# STM32L5x2 register map
File version: 1.3
Registers are 32-bit, read-write, reset 0x0 unless marked. A register's access mark holds for its fields unless they carry their own. Offsets are from the block's base; [hi:lo] are bit positions; {n}, {i} and the like mark numbered series.

## CRC — Cyclic redundancy check calculation unit
Base 0x40023000
Same registers: SEC_CRC 0x50023000
0x00 DR reset 0xFFFFFFFF — Data register
  [31:0] DR — Data register bits
0x04 IDR — Independent data register
  [7:0] IDR — General-purpose 8-bit data register bits
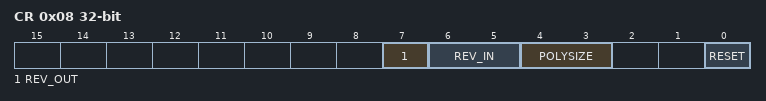
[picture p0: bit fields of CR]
0x08 CR access per field — Control register
  [7] REV_OUT rw — Reverse output data
  [6:5] REV_IN rw — Reverse input data
  [4:3] POLYSIZE rw — Polynomial size
  [0] RESET wo — RESET bit
0x10 INIT reset 0xFFFFFFFF — Initial CRC value
  [31:0] CRC_INIT — Programmable initial CRC value
0x14 POL reset 0x4C11DB7 — polynomial
  [31:0] Polynomialcoefficients — Programmable polynomial

## CRS — Clock recovery system
Base 0x40006000
Same registers: SEC_CRS 0x50006000
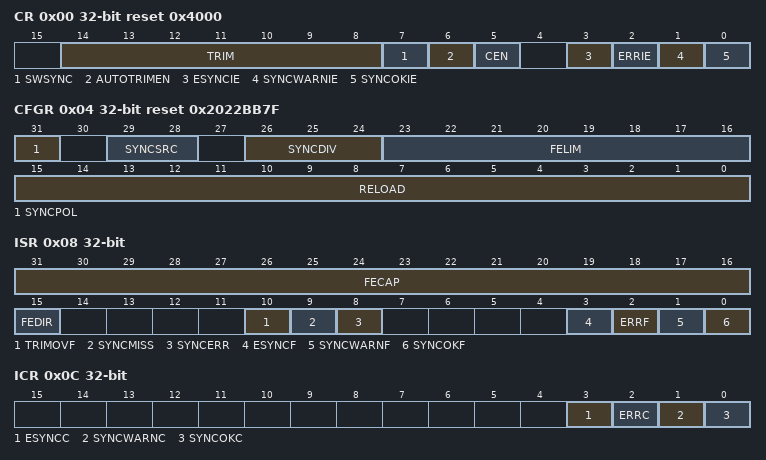
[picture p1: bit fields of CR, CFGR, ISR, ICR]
0x00 CR reset 0x4000 — control register
  [14:8] TRIM — HSI48 oscillator smooth trimming
  [7] SWSYNC — Generate software SYNC event
  [6] AUTOTRIMEN — Automatic trimming enable
  [5] CEN — Frequency error counter enable
  [3] ESYNCIE — Expected SYNC interrupt enable
  [2] ERRIE — Synchronization or trimming error interrupt enable
  [1] SYNCWARNIE — SYNC warning interrupt enable
  [0] SYNCOKIE — SYNC event OK interrupt enable
0x04 CFGR reset 0x2022BB7F — configuration register
  [31] SYNCPOL — SYNC polarity selection
  [29:28] SYNCSRC — SYNC signal source selection
  [26:24] SYNCDIV — SYNC divider
  [23:16] FELIM — Frequency error limit
  [15:0] RELOAD — Counter reload value
0x08 ISR ro — interrupt and status register
  [31:16] FECAP — Frequency error capture
  [15] FEDIR — Frequency error direction
  [10] TRIMOVF — Trimming overflow or underflow
  [9] SYNCMISS — SYNC missed
  [8] SYNCERR — SYNC error
  [3] ESYNCF — Expected SYNC flag
  [2] ERRF — Error flag
  [1] SYNCWARNF — SYNC warning flag
  [0] SYNCOKF — SYNC event OK flag
0x0C ICR — interrupt flag clear register
  [3] ESYNCC — Expected SYNC clear flag
  [2] ERRC — Error clear flag
  [1] SYNCWARNC — SYNC warning clear flag
  [0] SYNCOKC — SYNC event OK clear flag

## ADC_Common — Analog-to-Digital Converter
Base 0x42028300
Same registers: SEC_ADC_Common 0x52028300
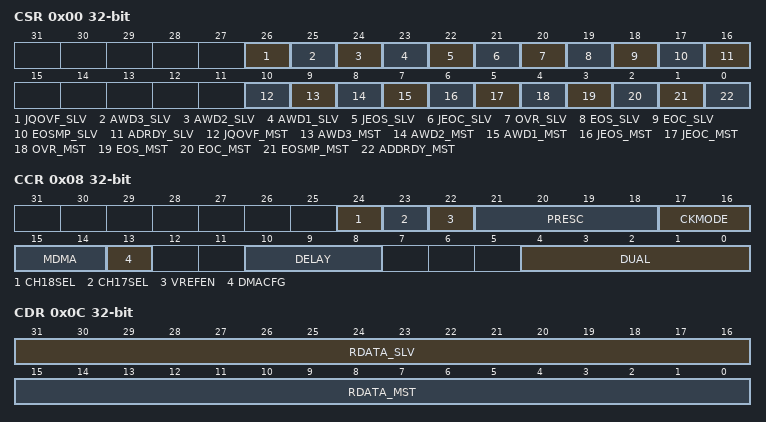
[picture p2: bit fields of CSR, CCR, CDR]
0x00 CSR ro — ADC Common status register
  [26] JQOVF_SLV, [25] AWD3_SLV, [24] AWD2_SLV, [23] AWD1_SLV, [22] JEOS_SLV, [21] JEOC_SLV, [20] OVR_SLV, [19] EOS_SLV, [18] EOC_SLV, [17] EOSMP_SLV, [16] ADRDY_SLV, [10] JQOVF_MST, [9] AWD3_MST, [8] AWD2_MST, [7] AWD1_MST, [6] JEOS_MST, [5] JEOC_MST, [4] OVR_MST, [3] EOS_MST, [2] EOC_MST, [1] EOSMP_MST, [0] ADDRDY_MST
0x08 CCR — ADC common control register
  [24] CH18SEL
  [23] CH17SEL
  [22] VREFEN — VREFINT enable
  [21:18] PRESC — ADC prescaler
  [17:16] CKMODE — ADC clock mode
  [15:14] MDMA
  [13] DMACFG
  [10:8] DELAY
  [4:0] DUAL
0x0C CDR ro — Common regular data register for dual mode
  [31:16] RDATA_SLV, [15:0] RDATA_MST

## ADC — Analog-to-Digital Converter
Base 0x42028000
Same registers: SEC_ADC 0x52028000
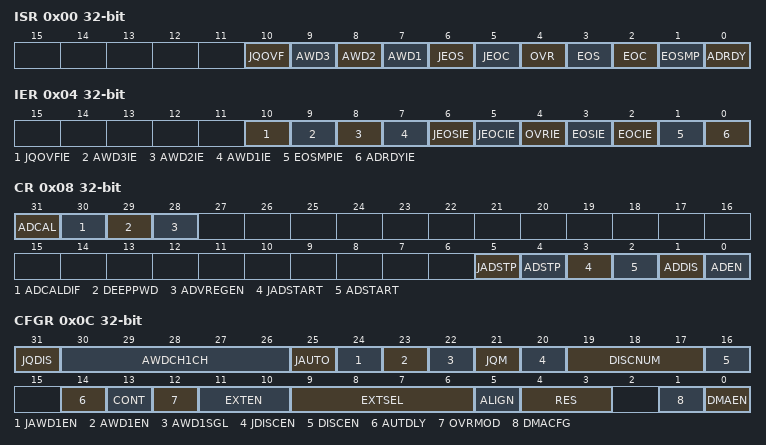
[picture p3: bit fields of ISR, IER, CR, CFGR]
0x00 ISR — interrupt and status register
  [10] JQOVF, [9] AWD3, [8] AWD2, [7] AWD1, [6] JEOS, [5] JEOC, [4] OVR, [3] EOS, [2] EOC, [1] EOSMP, [0] ADRDY
0x04 IER — interrupt enable register
  [10] JQOVFIE, [9] AWD3IE, [8] AWD2IE, [7] AWD1IE, [6] JEOSIE, [5] JEOCIE, [4] OVRIE, [3] EOSIE, [2] EOCIE, [1] EOSMPIE, [0] ADRDYIE
0x08 CR — control register
  [31] ADCAL, [30] ADCALDIF, [29] DEEPPWD, [28] ADVREGEN, [5] JADSTP, [4] ADSTP, [3] JADSTART, [2] ADSTART, [1] ADDIS, [0] ADEN
0x0C CFGR — configuration register
  [31] JQDIS, [30:26] AWDCH1CH, [25] JAUTO, [24] JAWD1EN, [23] AWD1EN, [22] AWD1SGL, [21] JQM, [20] JDISCEN, [19:17] DISCNUM, [16] DISCEN, [14] AUTDLY, [13] CONT, [12] OVRMOD, [11:10] EXTEN, [9:6] EXTSEL, [5] ALIGN, [4:3] RES, [1] DMACFG, [0] DMAEN
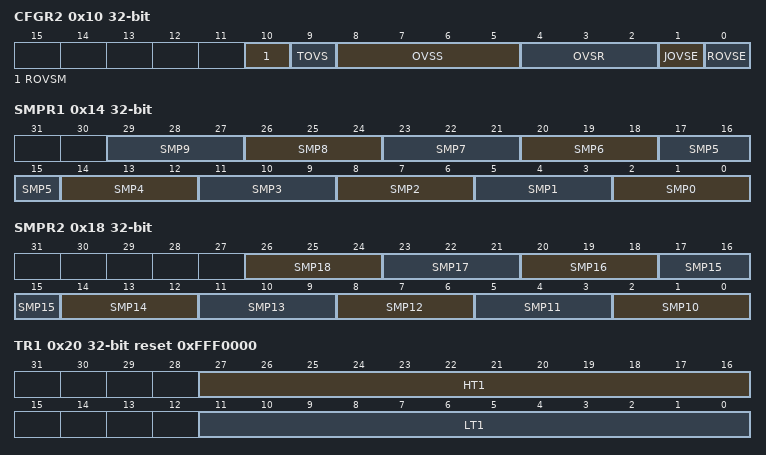
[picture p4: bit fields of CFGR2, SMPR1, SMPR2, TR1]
0x10 CFGR2 — configuration register
  [10] ROVSM — EXTEN
  [9] TOVS — EXTSEL
  [8:5] OVSS — ALIGN
  [4:2] OVSR — RES
  [1] JOVSE — DMACFG
  [0] ROVSE — DMAEN
0x14 SMPR1 — sample time register 1
  [3n+2:3n] SMP{n} (n=0..9)
0x18 SMPR2 — sample time register 2
  [3n-28:3n-30] SMP{n} (n=10..18)
0x20 TR1 reset 0xFFF0000 — watchdog threshold register 1
  [27:16] HT1, [11:0] LT1
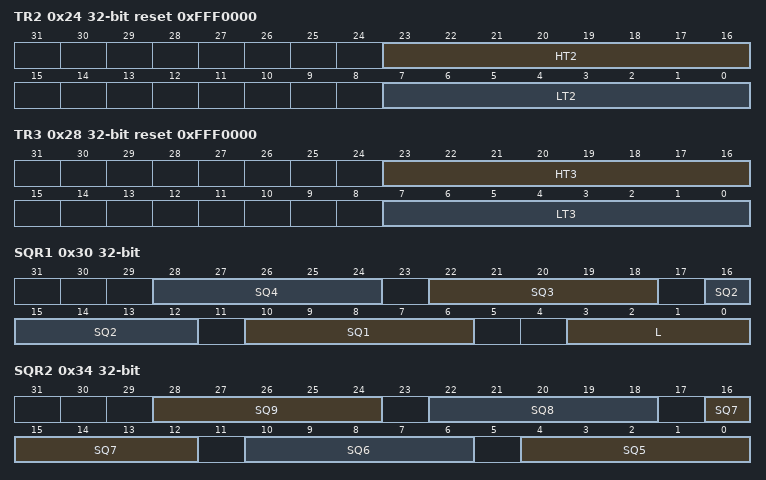
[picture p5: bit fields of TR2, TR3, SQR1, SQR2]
0x24 TR2 reset 0xFFF0000 — watchdog threshold register
  [23:16] HT2, [7:0] LT2
0x28 TR3 reset 0xFFF0000 — watchdog threshold register 3
  [23:16] HT3, [7:0] LT3
0x30 SQR1 — regular sequence register 1
  [6n+4:6n] SQ{n} (n=1..4), [3:0] L
0x34 SQR2 — regular sequence register 2
  [6n-26:6n-30] SQ{n} (n=5..9)
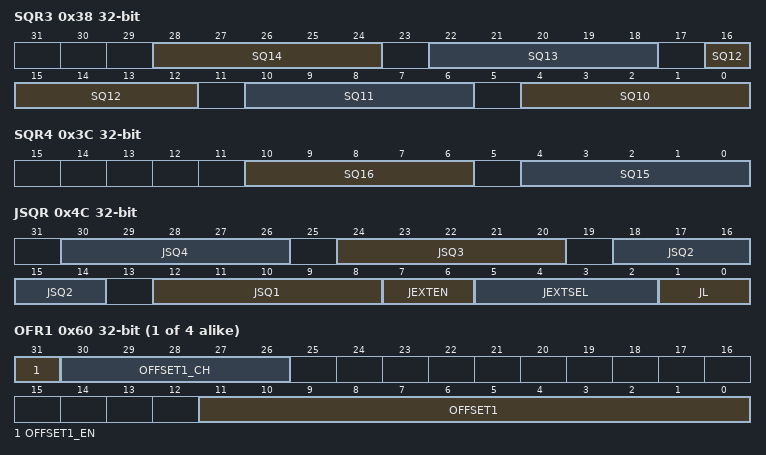
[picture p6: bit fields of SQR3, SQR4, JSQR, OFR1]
0x38 SQR3 — regular sequence register 3
  [6n-56:6n-60] SQ{n} (n=10..14)
0x3C SQR4 — regular sequence register 4
  [10:6] SQ16, [4:0] SQ15
0x40 DR ro — regular Data Register
  [15:0] RDATA — regularDATA
0x4C JSQR — injected sequence register
  [6n+6:6n+2] JSQ{n} (n=1..4), [7:6] JEXTEN, [5:2] JEXTSEL, [1:0] JL
{0x5C+4i} OFR{i} (i=1..4) — offset register {i}
  [31] OFFSET{i}_EN, [30:26] OFFSET{i}_CH, [11:0] OFFSET{i}
{0x7C+4i} JDR{i} ro (i=1..4) — injected data register {i}
  [15:0] JDATA — JDATA{i}
0xA0 AWD2CR — Analog Watchdog 2 Configuration Register
  [18:0] AWD2CH
0xA4 AWD3CR — Analog Watchdog 3 Configuration Register
  [18:0] AWD3CH
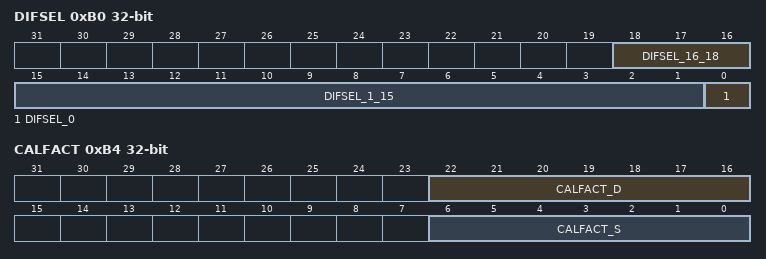
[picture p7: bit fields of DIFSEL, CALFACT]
0xB0 DIFSEL access per field — Differential Mode Selection Register 2
  [18:16] DIFSEL_16_18 ro — Differential mode for channels 18 to 16
  [15:1] DIFSEL_1_15 rw — Differential mode for channels 15 to 1
  [0] DIFSEL_0 ro — Differential mode for channel 0
0xB4 CALFACT — Calibration Factors
  [22:16] CALFACT_D, [6:0] CALFACT_S

## NVIC — Nested Vectored Interrupt Controller
Base 0xE000E100
{0x0+4i} ISER{i} (i=0..2) — Interrupt Set-Enable Register
  [31:0] SETENA
0x0C ISER3 — Interrupt Set-Enable Register
{0x80+4i} ICER{i} (i=0..2) — Interrupt Clear-Enable Register
  [31:0] CLRENA
0x8C ICER3 — Interrupt Clear-Enable Register
{0x100+4i} ISPR{i} (i=0..2) — Interrupt Set-Pending Register
  [31:0] SETPEND
0x10C ISPR3 — Interrupt Set-Pending Register
{0x180+4i} ICPR{i} (i=0..2) — Interrupt Clear-Pending Register
  [31:0] CLRPEND
0x18C ICPR3 — Interrupt Clear-Pending Register
{0x200+4i} IABR{i} ro (i=0..2) — Interrupt Active Bit Register
  [31:0] ACTIVE
0x20C IABR3 — Interrupt Active Bit Register
{0x280+4i} ITNS{i} (i=0..15)
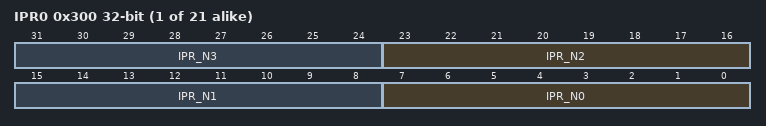
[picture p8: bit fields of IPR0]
{0x300+4i} IPR{i} (i=0..20) — Interrupt Priority Register
  [8n+7:8n] IPR_N{n} (n=0..3)
{0x300+4i} IPR{i} (i=21..29)

## NVIC_STIR — Nested vectored interrupt controller
Base 0xE000EF00
0x00 STIR — Software trigger interrupt register
  [8:0] INTID — Software generated interrupt ID

## SAU — Security Attribution Unit
Base 0xE000EDD0
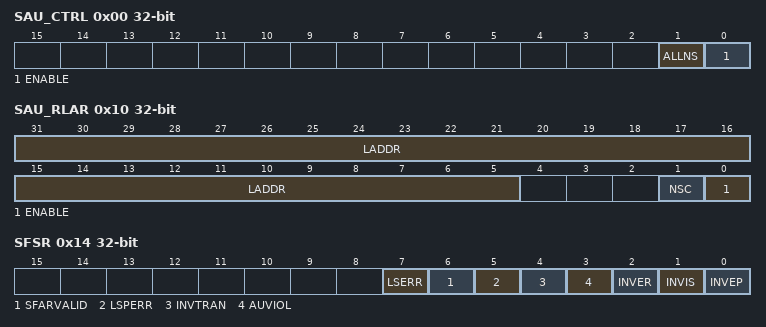
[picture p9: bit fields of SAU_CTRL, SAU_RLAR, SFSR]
0x00 SAU_CTRL — SAU Control Register
  [1] ALLNS — All Non-secure. When SAU_CTRL.ENABLE is 0 this bit controls if the memory is marked as Non-secure or Secure
  [0] ENABLE — Enables the SAU
0x04 SAU_TYPE reset 0x8 — Indicates the number of regions implemented by the Security Attribution Unit.
  [7:0] SREGION — The number of implemented SAU regions
0x08 SAU_RNR — Selects the region currently accessed by SAU_RBAR and SAU_RLAR
  [7:0] REGION — Indicates the SAU region accessed by SAU_RBAR and SAU_RLAR
0x0C SAU_RBAR — SAU Region Base Address Register
  [31:5] BADDR — Holds bits [31:5] of the base address for the selected SAU region
0x10 SAU_RLAR — SAU Region Limit Address Register
  [31:5] LADDR — Holds bits [31:5] of the limit address for the selected SAU region
  [1] NSC — Controls whether Non-secure state is permitted to execute an SG instruction from this region
  [0] ENABLE — SAU region enable
0x14 SFSR — Provides information about any security related faults
  [7] LSERR — Sticky flag indicating that an error occurred during lazy state activation or deactivation
  [6] SFARVALID — This bit is set when the SFAR register contains a valid value
  [5] LSPERR — Sticky flag indicating that an SAU or IDAU violation occurred during the lazy preservation of Floating-point state
  [4] INVTRAN — Sticky flag indicating that an exception was raised due to a branch that was not flagged as being domain crossing causing a transition from Secure to Non-secure memory
  [3] AUVIOL — Sticky flag indicating that an attempt was made to access parts of the address space that are marked as Secure with NS-Req for the transaction set to Non-secure
  [2] INVER — This can be caused by EXC_RETURN.DCRS being set to 0 when returning from an exception in the Non-secure state, or by EXC_RETURN.ES being set to 1 when returning from an exception in the Non-secure state
  [1] INVIS — This bit is set if the integrity signature in an exception stack frame is found to be invalid during the unstacking operation
  [0] INVEP — This bit is set if a function call from the Non-secure state or exception targets a non-SG instruction in the Secure state. This bit is also set if the target address is an SG instruction, but there is no matching SAU/IDAU region with the NSC flag set.
0x18 SFAR — Shows the address of the memory location that caused a Security violation
  [31:0] ADDRESS — The address of an access that caused an attribution unit violation
